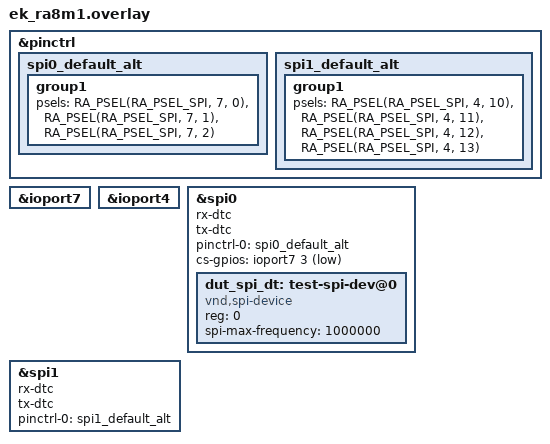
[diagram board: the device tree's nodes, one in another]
/*
 * Copyright (c) 2024 Renesas Electronics Corporation
 * SPDX-License-Identifier: Apache-2.0
 */

&pinctrl {
	spi0_default_alt: spi0_default_alt {
		group1 {
			/* MISO MOSI RSPCK SSL */
			psels = <RA_PSEL(RA_PSEL_SPI, 7, 0)>,
			<RA_PSEL(RA_PSEL_SPI, 7, 1)>,
			<RA_PSEL(RA_PSEL_SPI, 7, 2)>;
		};
	};

	spi1_default_alt: spi1_default_alt {
		group1 {
			/* MISO MOSI RSPCK SSL */
			psels = <RA_PSEL(RA_PSEL_SPI, 4, 10)>,
			<RA_PSEL(RA_PSEL_SPI, 4, 11)>,
			<RA_PSEL(RA_PSEL_SPI, 4, 12)>,
			<RA_PSEL(RA_PSEL_SPI, 4, 13)>;
		};
	};
};

&ioport7 {
	status = "okay";
};

&ioport4 {
	status = "okay";
};

&spi0 {
	rx-dtc;
	tx-dtc;
	status = "okay";
	pinctrl-0 = <&spi0_default_alt>;
	pinctrl-names = "default";
	cs-gpios = <&ioport7 3 GPIO_ACTIVE_LOW>;
	dut_spi_dt: test-spi-dev@0 {
		compatible = "vnd,spi-device";
		reg = <0>;
		spi-max-frequency = <1000000>;
	};
};

dut_spis: &spi1 {
	rx-dtc;
	tx-dtc;
	status = "okay";
	pinctrl-0 = <&spi1_default_alt>;
	pinctrl-names = "default";
};
